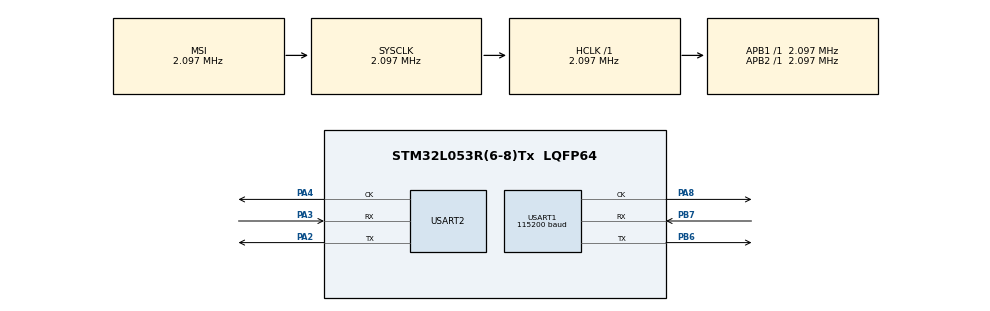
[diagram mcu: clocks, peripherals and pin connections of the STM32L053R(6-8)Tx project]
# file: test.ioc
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Mcu.Family=STM32L0
Mcu.Name=STM32L053R(6-8)Tx
Mcu.Package=LQFP64
PA2.Mode=Synchronous
PA2.Signal=USART2_TX
PA3.Mode=Synchronous
PA3.Signal=USART2_RX
PA4.Mode=Synchronous
PA4.Signal=USART2_CK
PA8.Mode=Synchronous
PA8.Signal=USART1_CK
PB6.Mode=Synchronous
PB6.Signal=USART1_TX
PB7.Mode=Synchronous
PB7.Signal=USART1_RX
ProjectManager.HeapSize=0x200
ProjectManager.StackSize=0x400
ProjectManager.TargetToolchain=STM32CubeIDE
RCC.AHBFreq_Value=2097000
RCC.APB1Freq_Value=2097000
RCC.APB1TimFreq_Value=2097000
RCC.APB2Freq_Value=2097000
RCC.APB2TimFreq_Value=2097000
RCC.HSE_VALUE=8000000
RCC.HSI16_VALUE=16000000
RCC.HSI48_VALUE=48000000
RCC.HSI_VALUE=16000000
RCC.LSE_VALUE=32768
RCC.MSI_VALUE=2097000
RCC.SYSCLKFreq_VALUE=2097000
RCC.VCOOutputFreq_Value=48000000
USART1.BaudRate=115200
USART1.VirtualMode-Synchronous=VM_SYNC
USART2.VirtualMode-Synchronous=VM_SYNC
board=custom

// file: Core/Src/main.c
/* USER CODE BEGIN Header */
/**
  ******************************************************************************
  * @file           : main.c
  * @brief          : Main program body
  ******************************************************************************
  * @attention
  *
  * <h2><center>&copy; Copyright (c) 2021 STMicroelectronics.
  * All rights reserved.</center></h2>
  *
  * This software component is licensed by ST under BSD 3-Clause license,
  * the "License"; You may not use this file except in compliance with the
  * License. You may obtain a copy of the License at:
  *                        opensource.org/licenses/BSD-3-Clause
  *
  ******************************************************************************
  */
#include <stdio.h>
#include "string.h"
/* USER CODE END Header */
#include "main.h"

USART_HandleTypeDef husart1;
USART_HandleTypeDef husart2;

void SystemClock_Config(void);
static void MX_GPIO_Init(void);
static void MX_USART2_Init(void);
static void MX_USART1_Init(void);

int main(void)
{

  /* MCU Configuration--------------------------------------------------------*/

  /* Reset of all peripherals, Initializes the Flash interface and the Systick. */
  HAL_Init();

  /* Configure the system clock */
  SystemClock_Config();

  /* Initialize all configured peripherals */
  MX_GPIO_Init();
  MX_USART2_Init();
  MX_USART1_Init();

  /* Infinite loop */
  /* USER CODE BEGIN WHILE */
  while (1)
  {
	  HAL_USART_Transmit(&husart2, (uint8_t *) "Hello, world!", strlen("Hello, world!"), 10);
	  HAL_USART_Transmit(&husart2, (uint8_t *) "Hello, world!", strlen("Hello, world!"), 10);
    /* USER CODE END WHILE */
  }
}

void SystemClock_Config(void)
{
  RCC_OscInitTypeDef RCC_OscInitStruct = {0};
  RCC_ClkInitTypeDef RCC_ClkInitStruct = {0};
  RCC_PeriphCLKInitTypeDef PeriphClkInit = {0};

  /** Configure the main internal regulator output voltage
  */
  __HAL_PWR_VOLTAGESCALING_CONFIG(PWR_REGULATOR_VOLTAGE_SCALE1);
  /** Initializes the RCC Oscillators according to the specified parameters
  * in the RCC_OscInitTypeDef structure.
  */
  RCC_OscInitStruct.OscillatorType = RCC_OSCILLATORTYPE_MSI;
  RCC_OscInitStruct.MSIState = RCC_MSI_ON;
  RCC_OscInitStruct.MSICalibrationValue = 0;
  RCC_OscInitStruct.MSIClockRange = RCC_MSIRANGE_5;
  RCC_OscInitStruct.PLL.PLLState = RCC_PLL_NONE;
  if (HAL_RCC_OscConfig(&RCC_OscInitStruct) != HAL_OK)
  {
    Error_Handler();
  }
  /** Initializes the CPU, AHB and APB buses clocks
  */
  RCC_ClkInitStruct.ClockType = RCC_CLOCKTYPE_HCLK|RCC_CLOCKTYPE_SYSCLK
                              |RCC_CLOCKTYPE_PCLK1|RCC_CLOCKTYPE_PCLK2;
  RCC_ClkInitStruct.SYSCLKSource = RCC_SYSCLKSOURCE_MSI;
  RCC_ClkInitStruct.AHBCLKDivider = RCC_SYSCLK_DIV1;
  RCC_ClkInitStruct.APB1CLKDivider = RCC_HCLK_DIV1;
  RCC_ClkInitStruct.APB2CLKDivider = RCC_HCLK_DIV1;

  if (HAL_RCC_ClockConfig(&RCC_ClkInitStruct, FLASH_LATENCY_0) != HAL_OK)
  {
    Error_Handler();
  }
  PeriphClkInit.PeriphClockSelection = RCC_PERIPHCLK_USART1|RCC_PERIPHCLK_USART2;
  PeriphClkInit.Usart1ClockSelection = RCC_USART1CLKSOURCE_PCLK2;
  PeriphClkInit.Usart2ClockSelection = RCC_USART2CLKSOURCE_PCLK1;
  if (HAL_RCCEx_PeriphCLKConfig(&PeriphClkInit) != HAL_OK)
  {
    Error_Handler();
  }
}

static void MX_USART1_Init(void)
{

  husart1.Instance = USART1;
  husart1.Init.BaudRate = 115200;
  husart1.Init.WordLength = USART_WORDLENGTH_8B;
  husart1.Init.StopBits = USART_STOPBITS_1;
  husart1.Init.Parity = USART_PARITY_NONE;
  husart1.Init.Mode = USART_MODE_TX_RX;
  husart1.Init.CLKPolarity = USART_POLARITY_LOW;
  husart1.Init.CLKPhase = USART_PHASE_1EDGE;
  husart1.Init.CLKLastBit = USART_LASTBIT_DISABLE;
  if (HAL_USART_Init(&husart1) != HAL_OK)
  {
    Error_Handler();
  }

}

static void MX_USART2_Init(void)
{

  husart2.Instance = USART2;
  husart2.Init.BaudRate = 115200;
  husart2.Init.WordLength = USART_WORDLENGTH_8B;
  husart2.Init.StopBits = USART_STOPBITS_1;
  husart2.Init.Parity = USART_PARITY_NONE;
  husart2.Init.Mode = USART_MODE_TX_RX;
  husart2.Init.CLKPolarity = USART_POLARITY_LOW;
  husart2.Init.CLKPhase = USART_PHASE_1EDGE;
  husart2.Init.CLKLastBit = USART_LASTBIT_DISABLE;
  if (HAL_USART_Init(&husart2) != HAL_OK)
  {
    Error_Handler();
  }

}

static void MX_GPIO_Init(void)
{

  /* GPIO Ports Clock Enable */
  __HAL_RCC_GPIOA_CLK_ENABLE();
  __HAL_RCC_GPIOB_CLK_ENABLE();

}

void Error_Handler(void)
{
  __disable_irq();
  while (1)
  {
  }
}

/************************ (C) COPYRIGHT STMicroelectronics *****END OF FILE****/
